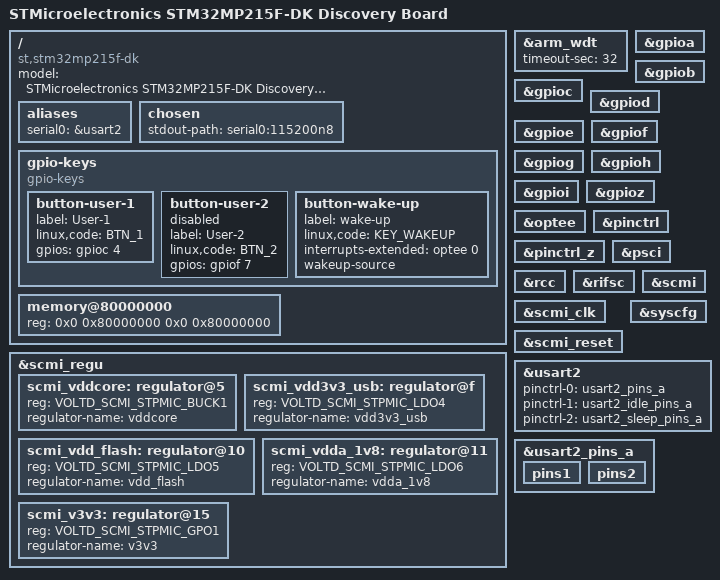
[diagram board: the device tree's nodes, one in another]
// SPDX-License-Identifier: (GPL-2.0-only OR BSD-3-Clause)
/*
 * Copyright (C) STMicroelectronics 2025 - All Rights Reserved
 * Author: Amelie Delaunay <amelie.delaunay@foss.st.com> for STMicroelectronics.
 */

/dts-v1/;

#include <dt-bindings/gpio/gpio.h>
#include <dt-bindings/input/input.h>
#include "stm32mp215.dtsi"
#include "stm32mp21xf.dtsi"
#include "stm32mp21-pinctrl.dtsi"
#include "stm32mp21xxan-pinctrl.dtsi"
#include "stm32mp215f-dk-resmem.dtsi"

/ {
	model = "STMicroelectronics STM32MP215F-DK Discovery Board";
	compatible = "st,stm32mp215f-dk", "st,stm32mp215";

	aliases {
		serial0 = &usart2;
	};

	chosen {
		stdout-path = "serial0:115200n8";
	};

	gpio-keys {
		compatible = "gpio-keys";

		button-user-1 {
			label = "User-1";
			linux,code = <BTN_1>;
			gpios = <&gpioc 4 GPIO_ACTIVE_HIGH>;
			status = "okay";
		};

		button-user-2 {
			label = "User-2";
			linux,code = <BTN_2>;
			gpios = <&gpiof 7 GPIO_ACTIVE_HIGH>;
			status = "disabled";
		};

		button-wake-up {
			label = "wake-up";
			linux,code = <KEY_WAKEUP>;
			interrupts-extended = <&optee 0>;
			wakeup-source;
			status = "okay";
		};
	};

	memory@80000000 {
		device_type = "memory";
		reg = <0x0 0x80000000 0x0 0x80000000>;
	};
};

&arm_wdt {
	timeout-sec = <32>;
	bootph-all;
	status = "okay";
};

&gpioa {
	bootph-all;
};

&gpiob {
	bootph-all;
};

&gpioc {
	bootph-all;
};

&gpiod {
	bootph-all;
};

&gpioe {
	bootph-all;
};

&gpiof {
	bootph-all;
};

&gpiog {
	bootph-all;
};

&gpioh {
	bootph-all;
};

&gpioi {
	bootph-all;
};

&gpioz {
	bootph-all;
};

&optee {
	bootph-all;
};

&pinctrl {
	bootph-all;
};

&pinctrl_z {
	bootph-all;
};

&psci {
	bootph-all;
};

&rcc {
	bootph-all;
};

&rifsc {
	bootph-all;
};

&scmi {
	bootph-all;
};

&scmi_clk {
	bootph-all;
};

&scmi_regu {
	scmi_vddcore: regulator@5 {
		reg = <VOLTD_SCMI_STPMIC_BUCK1>;
		regulator-name = "vddcore";
	};
	scmi_vdd3v3_usb: regulator@f {
		reg = <VOLTD_SCMI_STPMIC_LDO4>;
		regulator-name = "vdd3v3_usb";
	};
	scmi_vdd_flash: regulator@10 {
		reg = <VOLTD_SCMI_STPMIC_LDO5>;
		regulator-name = "vdd_flash";
	};
	scmi_vdda_1v8: regulator@11 {
		reg = <VOLTD_SCMI_STPMIC_LDO6>;
		regulator-name = "vdda_1v8";
	};
	scmi_v3v3: regulator@15 {
		reg = <VOLTD_SCMI_STPMIC_GPO1>;
		regulator-name = "v3v3";
	};
};

&scmi_reset {
	bootph-all;
};

&syscfg {
	bootph-all;
};

&usart2 {
	bootph-all;
	pinctrl-names = "default", "idle", "sleep";
	pinctrl-0 = <&usart2_pins_a>;
	pinctrl-1 = <&usart2_idle_pins_a>;
	pinctrl-2 = <&usart2_sleep_pins_a>;
	status = "okay";
};

&usart2_pins_a {
	bootph-all;
	pins1 {
		bootph-all;
	};
	pins2 {
		bootph-all;
	};
};
